# STM32F7x9 register map
File version: 1.6
CPU: CM7 r0p1, little endian, MPU, FPU, 4 interrupt priority bits
Registers are 32-bit, read-write, reset 0x0 unless marked. A register's access mark holds for its fields unless they carry their own. Offsets are from the block's base; [hi:lo] are bit positions.

## TIM6 — Basic timers
Base 0x40001000
Same registers: TIM7 0x40001400
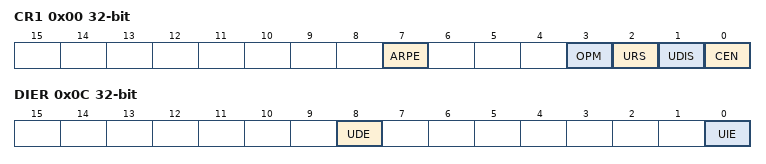
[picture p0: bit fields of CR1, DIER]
0x00 CR1 — control register 1
  [7] ARPE — Auto-reload preload enable
  [3] OPM — One-pulse mode
  [2] URS — Update request source
  [1] UDIS — Update disable
  [0] CEN — Counter enable
0x04 CR2 — control register 2
  [6:4] MMS — Master mode selection
0x0C DIER — DMA/Interrupt enable register
  [8] UDE — Update DMA request enable
  [0] UIE — Update interrupt enable
0x10 SR — status register
  [0] UIF — Update interrupt flag
0x14 EGR wo — event generation register
  [0] UG — Update generation
0x24 CNT — counter
  [15:0] CNT — Low counter value
0x28 PSC — prescaler
  [15:0] PSC — Prescaler value
0x2C ARR — auto-reload register
  [15:0] ARR — Low Auto-reload value

## Ethernet_MAC — Ethernet: media access control (MAC)
Base 0x40028000
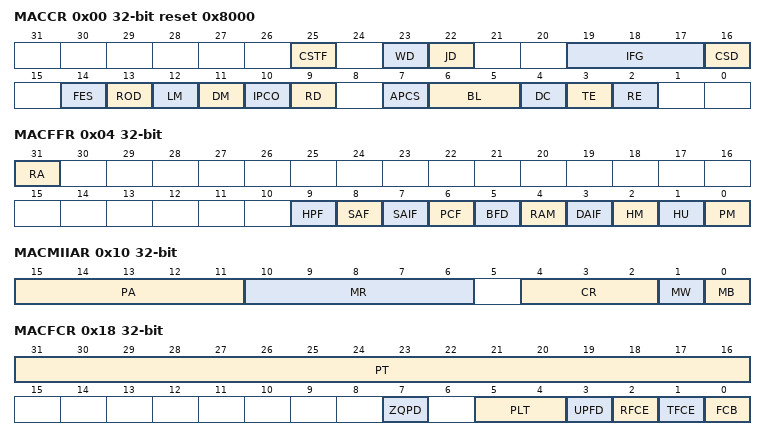
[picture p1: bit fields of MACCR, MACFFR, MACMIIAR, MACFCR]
0x00 MACCR reset 0x8000 — Ethernet MAC configuration register
  [25] CSTF, [23] WD, [22] JD, [19:17] IFG, [16] CSD, [14] FES, [13] ROD, [12] LM, [11] DM, [10] IPCO, [9] RD, [7] APCS, [6:5] BL, [4] DC, [3] TE, [2] RE
0x04 MACFFR — Ethernet MAC frame filter register
  [31] RA, [9] HPF, [8] SAF, [7] SAIF, [6] PCF, [5] BFD, [4] RAM, [3] DAIF, [2] HM, [1] HU, [0] PM
0x08 MACHTHR — Ethernet MAC hash table high register
  [31:0] HTH
0x0C MACHTLR — Ethernet MAC hash table low register
  [31:0] HTL
0x10 MACMIIAR — Ethernet MAC MII address register
  [15:11] PA, [10:6] MR, [4:2] CR, [1] MW, [0] MB
0x14 MACMIIDR — Ethernet MAC MII data register
  [15:0] TD
0x18 MACFCR — Ethernet MAC flow control register
  [31:16] PT, [7] ZQPD, [5:4] PLT, [3] UPFD, [2] RFCE, [1] TFCE, [0] FCB
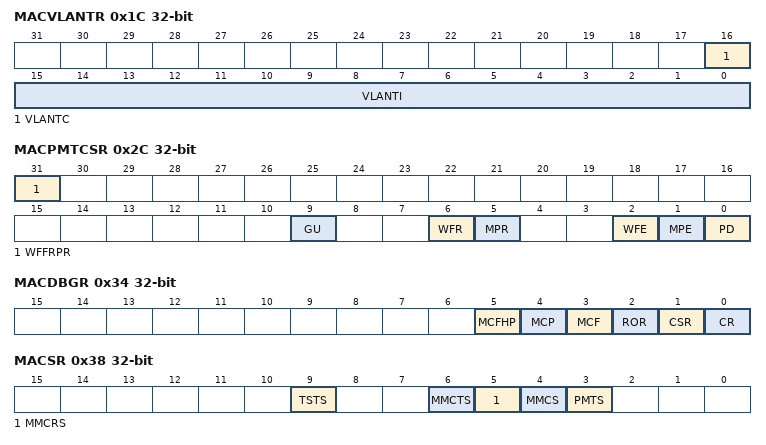
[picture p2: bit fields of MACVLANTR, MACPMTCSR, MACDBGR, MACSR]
0x1C MACVLANTR — Ethernet MAC VLAN tag register
  [16] VLANTC, [15:0] VLANTI
0x2C MACPMTCSR — Ethernet MAC PMT control and status register
  [31] WFFRPR, [9] GU, [6] WFR, [5] MPR, [2] WFE, [1] MPE, [0] PD
0x34 MACDBGR ro — Ethernet MAC debug register
  [5] MCFHP, [4] MCP, [3] MCF, [2] ROR, [1] CSR, [0] CR
0x38 MACSR access per field — Ethernet MAC interrupt status register
  [9] TSTS rw
  [6] MMCTS ro
  [5] MMCRS ro
  [4] MMCS ro — PMTS
  [3] PMTS ro
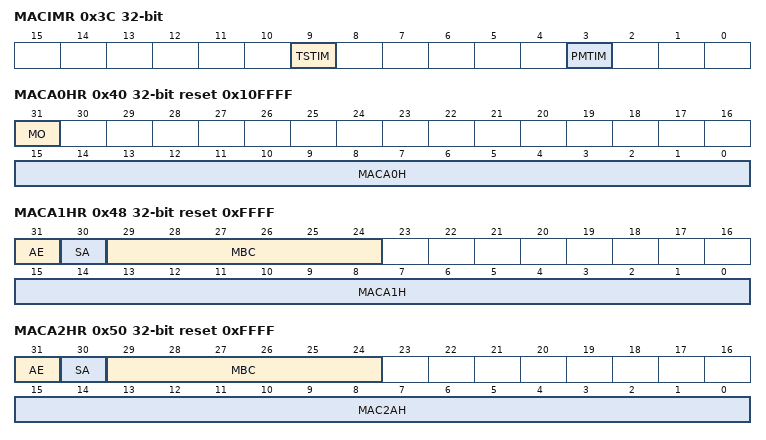
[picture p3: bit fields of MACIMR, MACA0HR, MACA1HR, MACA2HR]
0x3C MACIMR — Ethernet MAC interrupt mask register
  [9] TSTIM, [3] PMTIM
0x40 MACA0HR access per field reset 0x10FFFF — Ethernet MAC address 0 high register
  [31] MO ro — Always 1
  [15:0] MACA0H rw — MAC address0 high
0x44 MACA0LR reset 0xFFFFFFFF — Ethernet MAC address 0 low register
  [31:0] MACA0L — 0
0x48 MACA1HR reset 0xFFFF — Ethernet MAC address 1 high register
  [31] AE, [30] SA, [29:24] MBC, [15:0] MACA1H
0x4C MACA1LR reset 0xFFFFFFFF — Ethernet MAC address1 low register
0x50 MACA2HR reset 0xFFFF — Ethernet MAC address 2 high register
  [31] AE, [30] SA, [29:24] MBC, [15:0] MAC2AH
0x54 MACA2LR reset 0xFFFFFFFF — Ethernet MAC address 2 low register
  [30:0] MACA2L
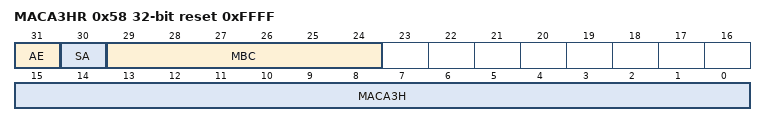
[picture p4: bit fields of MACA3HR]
0x58 MACA3HR reset 0xFFFF — Ethernet MAC address 3 high register
  [31] AE, [30] SA, [29:24] MBC, [15:0] MACA3H
0x5C MACA3LR reset 0xFFFFFFFF — Ethernet MAC address 3 low register
  [31:0] MBCA3L
0x60 MACRWUFFER reset 0xFFFFFFFF — Ethernet MAC remote wakeup frame filter register

## CRC — Cryptographic processor
Base 0x40023000
0x00 DR reset 0xFFFFFFFF — Data register
  [31:0] DR — Data Register
0x04 IDR — Independent Data register
  [7:0] IDR
0x08 CR wo — Control register
  [0] CR — Control regidter
0x0C INIT — Initial CRC value
  [31:0] CRC_INIT — Programmable initial CRC value
0x10 POL — CRC polynomial
  [31:0] POL — Programmable polynomial

## Flash
Base 0x40023C00
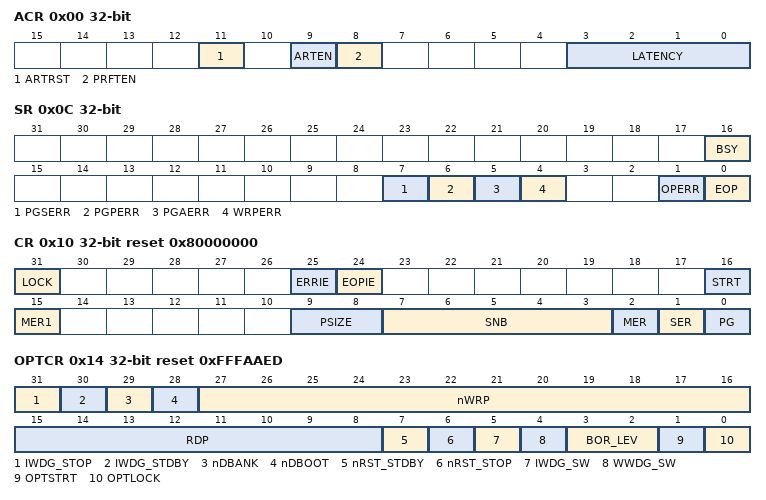
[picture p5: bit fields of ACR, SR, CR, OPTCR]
0x00 ACR — Flash access control register
  [11] ARTRST — ART Accelerator reset
  [9] ARTEN — ART Accelerator Enable
  [8] PRFTEN — Prefetch enable
  [3:0] LATENCY
0x04 KEYR wo — Flash key register
  [31:0] KEY — FPEC key
0x08 OPTKEYR wo — Flash option key register
  [31:0] OPTKEY — Option byte key
0x0C SR access per field — Status register
  [16] BSY ro — Busy
  [7] PGSERR rw — Programming sequence error
  [6] PGPERR rw — Programming parallelism error
  [5] PGAERR rw — Programming alignment error
  [4] WRPERR rw — Write protection error
  [1] OPERR rw — Operation error
  [0] EOP rw — End of operation
0x10 CR reset 0x80000000 — Control register
  [31] LOCK
  [25] ERRIE — Error interrupt enable
  [24] EOPIE — End of operation interrupt enable
  [16] STRT — Start
  [15] MER1 — Mass Erase of sectors 12 to 23
  [9:8] PSIZE — Program size
  [7:3] SNB — Sector number
  [2] MER — Mass Erase of sectors 0 to 11
  [1] SER — Sector Erase
  [0] PG — Programming
0x14 OPTCR reset 0xFFFAAED — Flash option control register
  [31] IWDG_STOP — Independent watchdog counter freeze in Stop mode
  [30] IWDG_STDBY — Independent watchdog counter freeze in standby mode
  [29] nDBANK — Not dual bank mode
  [28] nDBOOT — Dual Boot mode (valid only when nDBANK=0)
  [27:16] nWRP — Not write protect
  [15:8] RDP — Read protect
  [7] nRST_STDBY — User option bytes
  [6] nRST_STOP — User option bytes
  [5] IWDG_SW — User option bytes
  [4] WWDG_SW — User option bytes
  [3:2] BOR_LEV — BOR reset Level
  [1] OPTSTRT — Option start
  [0] OPTLOCK — Option lock
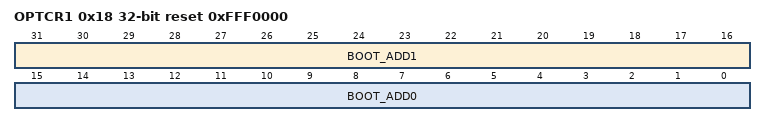
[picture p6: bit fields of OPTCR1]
0x18 OPTCR1 reset 0xFFF0000 — Flash option control register 1
  [31:16] BOOT_ADD1 — Boot base address when Boot pin =1
  [15:0] BOOT_ADD0 — Boot base address when Boot pin =0
